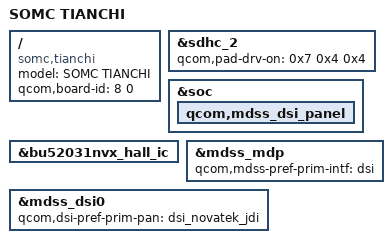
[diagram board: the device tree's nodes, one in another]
/* Copyright (c) 2013-2014, The Linux Foundation. All rights reserved.
 * Copyright (C) 2014 Sony Mobile Communications Inc.
 *
 * This program is free software; you can redistribute it and/or modify
 * it under the terms of the GNU General Public License version 2 and
 * only version 2 as published by the Free Software Foundation.
 *
 * This program is distributed in the hope that it will be useful,
 * but WITHOUT ANY WARRANTY; without even the implied warranty of
 * MERCHANTABILITY or FITNESS FOR A PARTICULAR PURPOSE.  See the
 * GNU General Public License for more details.
 *
 * NOTE: This file has been modified by Sony Mobile Communications Inc.
 * Modifications are licensed under the License.
 */

/dts-v1/;
/include/ "msm8926-v1-tianchi.dtsi"
/include/ "msm8226-tianchi_dsds.dtsi"
/include/ "dsi-tianchi_dsds-panel.dtsi"
/include/ "msm8226-camera-sensor-tianchi.dtsi"

/ {
	model = "SOMC TIANCHI";
	compatible = "somc,tianchi", "qcom,msm8926-mtp", "qcom,msm8926", "qcom,mtp";
	qcom,board-id = <8 0>;
};

&sdhc_2 {
       qcom,pad-drv-on = <0x7 0x4 0x4>; /* 16mA, 10mA, 10mA */
};

&soc {
        qcom,mdss_dsi_panel {
                status = "ok";
        };
};

&bu52031nvx_hall_ic {
	status = "ok";
};

&mdss_mdp {
	qcom,mdss-pref-prim-intf = "dsi";
};

&mdss_dsi0 {
	qcom,dsi-pref-prim-pan = <&dsi_novatek_jdi>;
};
